# CY8C5588AXI_060ES1 register map
File version: 0.1
CY8C55
Registers are 8-bit, read-write, no defined reset value unless marked. A register's access mark holds for its fields unless they carry their own. Offsets are from the block's base; lines under a group give offsets from that group; [hi:lo] are bit positions; {n}, {i} and the like mark numbered series; 'fields as' and 'values as' point back to an identical list; <NAME> marks a mode.

## Memory map
0x400049C8 NEOMOTE_1_I2C_0 size 0x14
0x40006428 uart_solinst size 0x140 — UART
0x4000642C uart_ultrasonic size 0x41 — UART
0x4000644A NEOMOTE_1_UART_MOTE size 0x120 — UART

## uart_ultrasonic — UART
Base 0x4000642C
0x00 RX_uart_ultrasonic_RX_ADDRESS1 — RX Address1 Register
0x10 RX_uart_ultrasonic_RX_ADDRESS2 — RX Address2 Register
0x20 RX_uart_ultrasonic_RX_DATA — RX Data Register
0x21 TX_uart_ultrasonic_TX_DATA — TX Data Register
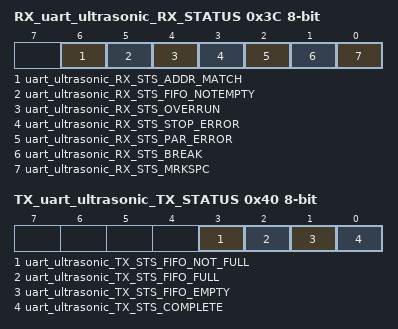
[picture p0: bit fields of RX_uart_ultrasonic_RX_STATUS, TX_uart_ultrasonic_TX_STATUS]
0x3C RX_uart_ultrasonic_RX_STATUS — RX status register
  [6] uart_ultrasonic_RX_STS_ADDR_MATCH ro, [5] uart_ultrasonic_RX_STS_FIFO_NOTEMPTY ro, [4] uart_ultrasonic_RX_STS_OVERRUN ro, [3] uart_ultrasonic_RX_STS_STOP_ERROR ro, [2] uart_ultrasonic_RX_STS_PAR_ERROR ro, [1] uart_ultrasonic_RX_STS_BREAK ro, [0] uart_ultrasonic_RX_STS_MRKSPC ro
0x40 TX_uart_ultrasonic_TX_STATUS — TX status register
  [3] uart_ultrasonic_TX_STS_FIFO_NOT_FULL ro, [2] uart_ultrasonic_TX_STS_FIFO_FULL ro, [1] uart_ultrasonic_TX_STS_FIFO_EMPTY ro, [0] uart_ultrasonic_TX_STS_COMPLETE ro

## NEOMOTE_1_I2C_0
Base 0x400049C8
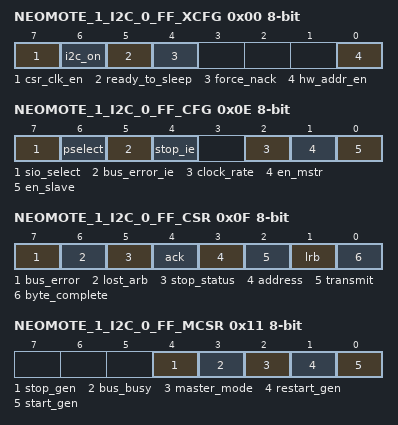
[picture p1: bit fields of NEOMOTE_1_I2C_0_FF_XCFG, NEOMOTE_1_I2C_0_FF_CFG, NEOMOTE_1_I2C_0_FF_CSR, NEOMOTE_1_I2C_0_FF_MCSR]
0x00 NEOMOTE_1_I2C_0_FF_XCFG — Extended Configuration Register: I2C_XCFG
  [7] csr_clk_en, [6] i2c_on, [5] ready_to_sleep ro, [4] force_nack, [0] hw_addr_en
0x02 NEOMOTE_1_I2C_0_FF_ADDR — Slave Adddress Register: I2C_ADR
  [6:0] slave_address — This register holds the slave's 7-bit address.
0x0E NEOMOTE_1_I2C_0_FF_CFG — Configuration Register: I2C_CFG
  [7] sio_select, [6] pselect, [5] bus_error_ie, [4] stop_ie, [2] clock_rate, [1] en_mstr, [0] en_slave
0x0F NEOMOTE_1_I2C_0_FF_CSR — Control and Status Register: I2C_CSR
  [7] bus_error, [6] lost_arb, [5] stop_status, [4] ack, [3] address, [2] transmit, [1] lrb, [0] byte_complete
0x10 NEOMOTE_1_I2C_0_FF_DATA — Data Register: I2C_D
  [7:0] data — This register provides read/write access to the Shift register.
0x11 NEOMOTE_1_I2C_0_FF_MCSR — Master Control and Status Register: I2C_MCSR
  [4] stop_gen, [3] bus_busy ro, [2] master_mode ro, [1] restart_gen, [0] start_gen
0x13 NEOMOTE_1_I2C_0_FF__CLK_DIV — Divider of BUS_CLK presented power of 2: I2C_CLK_DIV
  [2:0] Div

## NEOMOTE_1_UART_MOTE — UART
Base 0x4000644A
0x00 TX_NEOMOTE_1_UART_MOTE_TX_DATA — TX Data Register
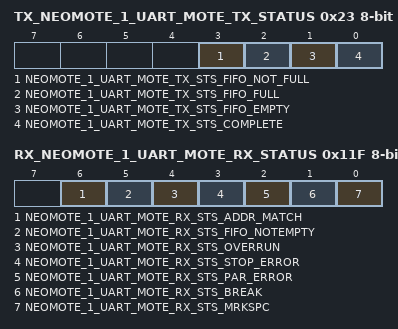
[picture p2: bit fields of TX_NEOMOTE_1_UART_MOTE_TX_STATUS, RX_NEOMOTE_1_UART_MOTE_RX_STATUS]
0x23 TX_NEOMOTE_1_UART_MOTE_TX_STATUS — TX status register
  [3] NEOMOTE_1_UART_MOTE_TX_STS_FIFO_NOT_FULL ro, [2] NEOMOTE_1_UART_MOTE_TX_STS_FIFO_FULL ro, [1] NEOMOTE_1_UART_MOTE_TX_STS_FIFO_EMPTY ro, [0] NEOMOTE_1_UART_MOTE_TX_STS_COMPLETE ro
0xDF RX_NEOMOTE_1_UART_MOTE_RX_ADDRESS1 — RX Address1 Register
0xEF RX_NEOMOTE_1_UART_MOTE_RX_ADDRESS2 — RX Address2 Register
0xFF RX_NEOMOTE_1_UART_MOTE_RX_DATA — RX Data Register
0x11F RX_NEOMOTE_1_UART_MOTE_RX_STATUS — RX status register
  [6] NEOMOTE_1_UART_MOTE_RX_STS_ADDR_MATCH ro, [5] NEOMOTE_1_UART_MOTE_RX_STS_FIFO_NOTEMPTY ro, [4] NEOMOTE_1_UART_MOTE_RX_STS_OVERRUN ro, [3] NEOMOTE_1_UART_MOTE_RX_STS_STOP_ERROR ro, [2] NEOMOTE_1_UART_MOTE_RX_STS_PAR_ERROR ro, [1] NEOMOTE_1_UART_MOTE_RX_STS_BREAK ro, [0] NEOMOTE_1_UART_MOTE_RX_STS_MRKSPC ro

## uart_solinst — UART
Base 0x40006428
0x00 RX_uart_solinst_RX_ADDRESS1 — RX Address1 Register
0x10 RX_uart_solinst_RX_ADDRESS2 — RX Address2 Register
0x1E TX_uart_solinst_TX_DATA — TX Data Register
0x20 RX_uart_solinst_RX_DATA — RX Data Register
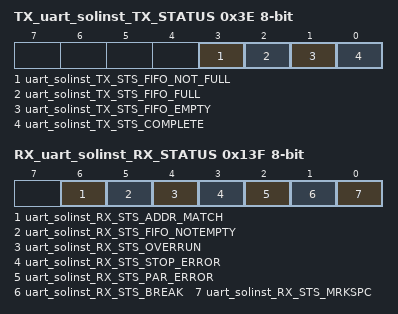
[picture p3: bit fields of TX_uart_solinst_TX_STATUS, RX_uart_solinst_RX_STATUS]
0x3E TX_uart_solinst_TX_STATUS — TX status register
  [3] uart_solinst_TX_STS_FIFO_NOT_FULL ro, [2] uart_solinst_TX_STS_FIFO_FULL ro, [1] uart_solinst_TX_STS_FIFO_EMPTY ro, [0] uart_solinst_TX_STS_COMPLETE ro
0x13F RX_uart_solinst_RX_STATUS — RX status register
  [6] uart_solinst_RX_STS_ADDR_MATCH ro, [5] uart_solinst_RX_STS_FIFO_NOTEMPTY ro, [4] uart_solinst_RX_STS_OVERRUN ro, [3] uart_solinst_RX_STS_STOP_ERROR ro, [2] uart_solinst_RX_STS_PAR_ERROR ro, [1] uart_solinst_RX_STS_BREAK ro, [0] uart_solinst_RX_STS_MRKSPC ro
